# rCSL_ectl_001 register map
Vendor: Texas Instruments
Peripheral module from a debugger description file (folder OMAPL138_C6748).
Registers are 32-bit, access not given, reset 0x0 unless marked. A register's access mark holds for its fields unless they carry their own. Offsets are as the file gives them; lines under a group give offsets from that group; [hi:lo] are bit positions; {n}, {i} and the like mark numbered series; 'fields as' and 'values as' point back to an identical list; <NAME> marks a mode.

## ECTL — Common Platform Gigabit ethernet MAC SubSystem RMII
0x00 REVID ro reset 0x4EC80100 — Transmit Identification and Version Register
  [31:0] REV — REV ID
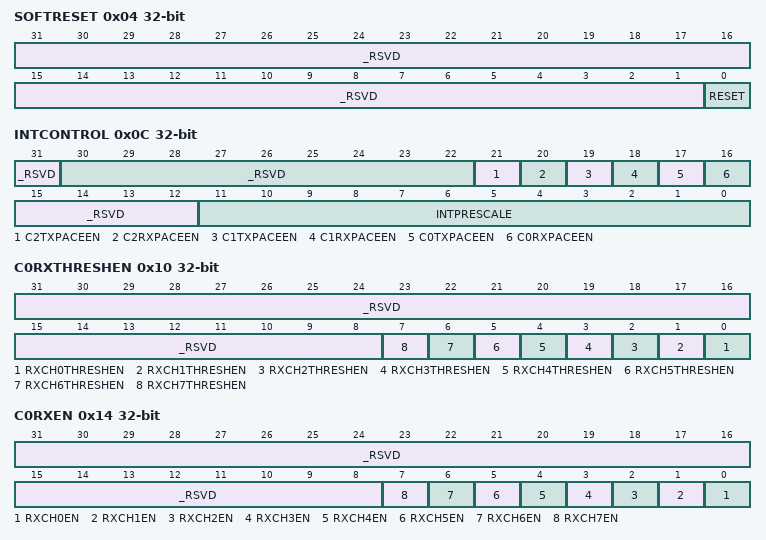
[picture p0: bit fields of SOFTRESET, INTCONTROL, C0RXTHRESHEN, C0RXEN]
0x04 SOFTRESET — Software Reset Register
  [31:1] _RSVD — (access N)
  [0] RESET rw — Soft Reset for CPGMACSS_R modules INT, REGS, CPPI
0x0C INTCONTROL — Interrupt Control Register
  [31] _RSVD — Interrupt Test (access N)
  [30:22] _RSVD — (access N)
  [21] C2TXPACEEN rw — C2_TX_PULSE Pacing
    0=DISABLE; 1=ENABLE
  [20] C2RXPACEEN rw — C2_RX_PULSE Pacing
    0=DISABLE; 1=ENABLE
  [19] C1TXPACEEN rw — C1_TX_PULSE Pacing
    0=DISABLE; 1=ENABLE
  [18] C1RXPACEEN rw — C1_RX_PULSE Pacing
    0=DISABLE; 1=ENABLE
  [17] C0TXPACEEN rw — C0_TX_PULSE Pacing
    0=DISABLE; 1=ENABLE
  [16] C0RXPACEEN rw — C0_RX_PULSE Pacing
    0=DISABLE; 1=ENABLE
  [15:12] _RSVD — (access N)
  [11:0] INTPRESCALE rw — Interrupt Counter Prescaler (Number of 4us VBUSP_CLKs)
0x10 C0RXTHRESHEN — Core 0 Receive Threshold Enable Register
  [31:8] _RSVD — (access N)
  [n] RXCH{n}THRESHEN rw (n=0..7) — Corresponds to the interrupt for RXCH{n}THRESH
    0=DISABLE; 1=ENABLE
0x14 C0RXEN — Core 0 Receive Enable Register
  [31:8] _RSVD — (access N)
  [n] RXCH{n}EN rw (n=0..7) — Corresponds to the interrupt for RXCH{n}EN
    0=DISABLE; 1=ENABLE
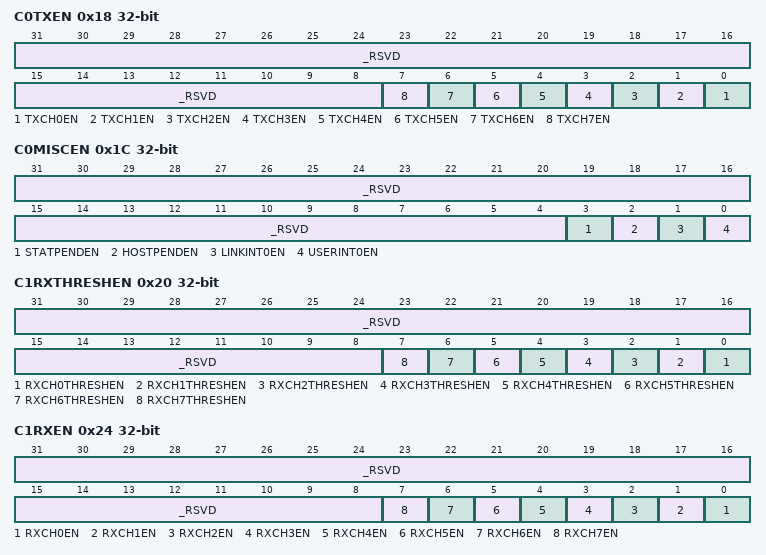
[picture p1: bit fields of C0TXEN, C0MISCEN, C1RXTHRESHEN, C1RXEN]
0x18 C0TXEN — Core 0 Transmit Enable Register
  [31:8] _RSVD — (access N)
  [n] TXCH{n}EN rw (n=0..7) — Corresponds to the interrupt for TXCH{n}EN
    0=DISABLE; 1=ENABLE
0x1C C0MISCEN — Core 0 Misc Interrupt Enable Register
  [31:4] _RSVD — (access N)
  [3] STATPENDEN rw — Status Pending Interrupt
    0=DISABLE; 1=ENABLE
  [2] HOSTPENDEN rw — Host Pending Interrupt
    0=DISABLE; 1=ENABLE
  [1] LINKINT0EN rw — MDIO LINKINT[0]
    0=DISABLE; 1=ENABLE
  [0] USERINT0EN rw — MDIO USERINT[0]
    0=DISABLE; 1=ENABLE
0x20 C1RXTHRESHEN — Core 1 Receive Threshold Enable Register
  fields as C0RXTHRESHEN
0x24 C1RXEN — Core 1 Receive Enable Register
  fields as C0RXEN
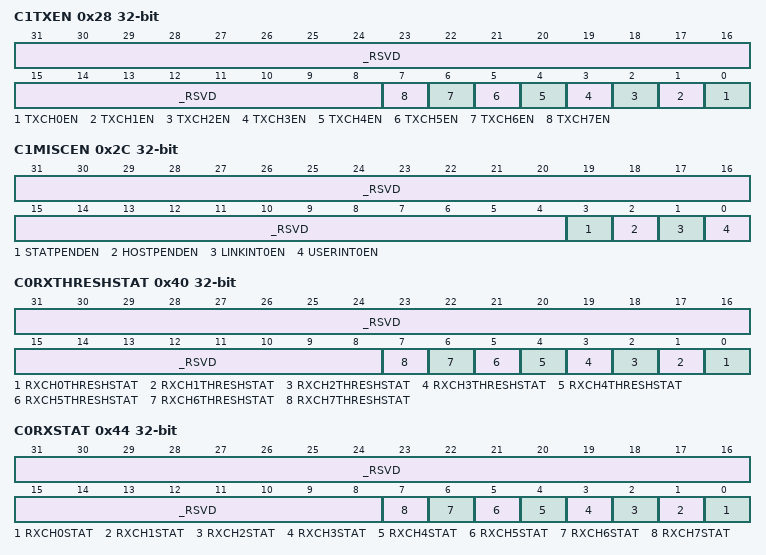
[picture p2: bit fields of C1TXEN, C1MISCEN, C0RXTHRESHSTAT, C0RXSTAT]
0x28 C1TXEN — Core 1 Transmit Enable Register
  fields as C0TXEN
0x2C C1MISCEN — Core 1 Misc Enable Register
  fields as C0MISCEN
0x40 C0RXTHRESHSTAT — Core 0 Receive Threshold Status Register
  [31:8] _RSVD — (access N)
  [n] RXCH{n}THRESHSTAT ro (n=0..7) — Corresponds to the interrupt for RXCH{n}THRESH
0x44 C0RXSTAT — Core 0 Receive Status Register
  [31:8] _RSVD — (access N)
  [n] RXCH{n}STAT ro (n=0..7) — Corresponds to the interrupt for RXCH{n}STAT
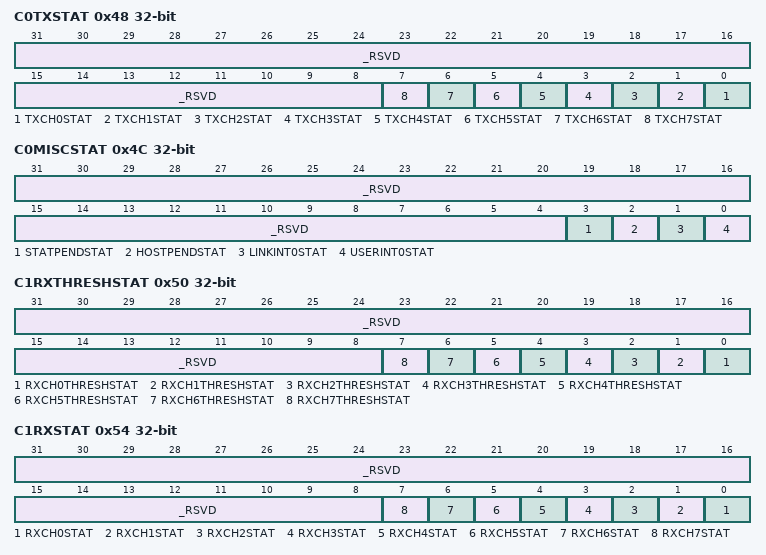
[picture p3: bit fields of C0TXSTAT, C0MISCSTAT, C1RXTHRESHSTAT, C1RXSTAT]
0x48 C0TXSTAT — Core 0 Transmit Status Register
  [31:8] _RSVD — (access N)
  [n] TXCH{n}STAT ro (n=0..7) — Corresponds to the interrupt for TXCH{n}STAT
0x4C C0MISCSTAT — Core 0 Misc Interrupt Status Register
  [31:4] _RSVD — (access N)
  [3] STATPENDSTAT ro
  [2] HOSTPENDSTAT ro
  [1] LINKINT0STAT ro
  [0] USERINT0STAT ro
0x50 C1RXTHRESHSTAT — Core 1 Receive Threshold Status Register
  fields as C0RXTHRESHSTAT
0x54 C1RXSTAT — Core 1 Receive Status Register
  fields as C0RXSTAT
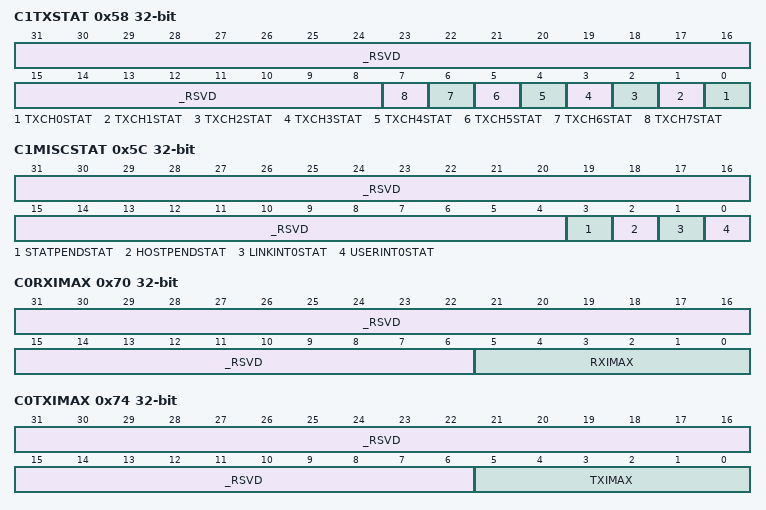
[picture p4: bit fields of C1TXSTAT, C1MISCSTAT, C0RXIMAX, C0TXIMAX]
0x58 C1TXSTAT — Core 1 Transmit Status Register
  fields as C0TXSTAT
0x5C C1MISCSTAT — Core 1 Misc Interrupt Status Register
  fields as C0MISCSTAT
0x60 RSVD — Core 2 Receive Threshold Status Register
  [31:0] _RSVD — (access N)
0x70 C0RXIMAX — Core 0 Receive Interrupts per Millisecond Register
  [31:6] _RSVD — (access N)
  [5:0] RXIMAX rw — Core 0 Receive Interrupts per Millisecond for C0RXPULSE
0x74 C0TXIMAX — Core 0 Transmit Interrupts per Millisecond Register
  [31:6] _RSVD — (access N)
  [5:0] TXIMAX rw — Core 0 Receive Interrupts per Millisecond for C0TXPULSE
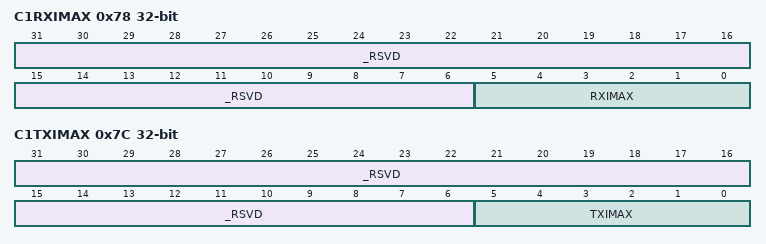
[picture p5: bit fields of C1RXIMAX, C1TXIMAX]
0x78 C1RXIMAX — Core 1 Receive Interrupts per Millisecond Register
  [31:6] _RSVD — (access N)
  [5:0] RXIMAX rw — Core 1 Receive Interrupts per Millisecond for C1RXPULSE
0x7C C1TXIMAX — Core 1 Transmit Interrupts per Millisecond Register
  [31:6] _RSVD — (access N)
  [5:0] TXIMAX rw — Core 1 Receive Interrupts per Millisecond for C1TXPULSE
